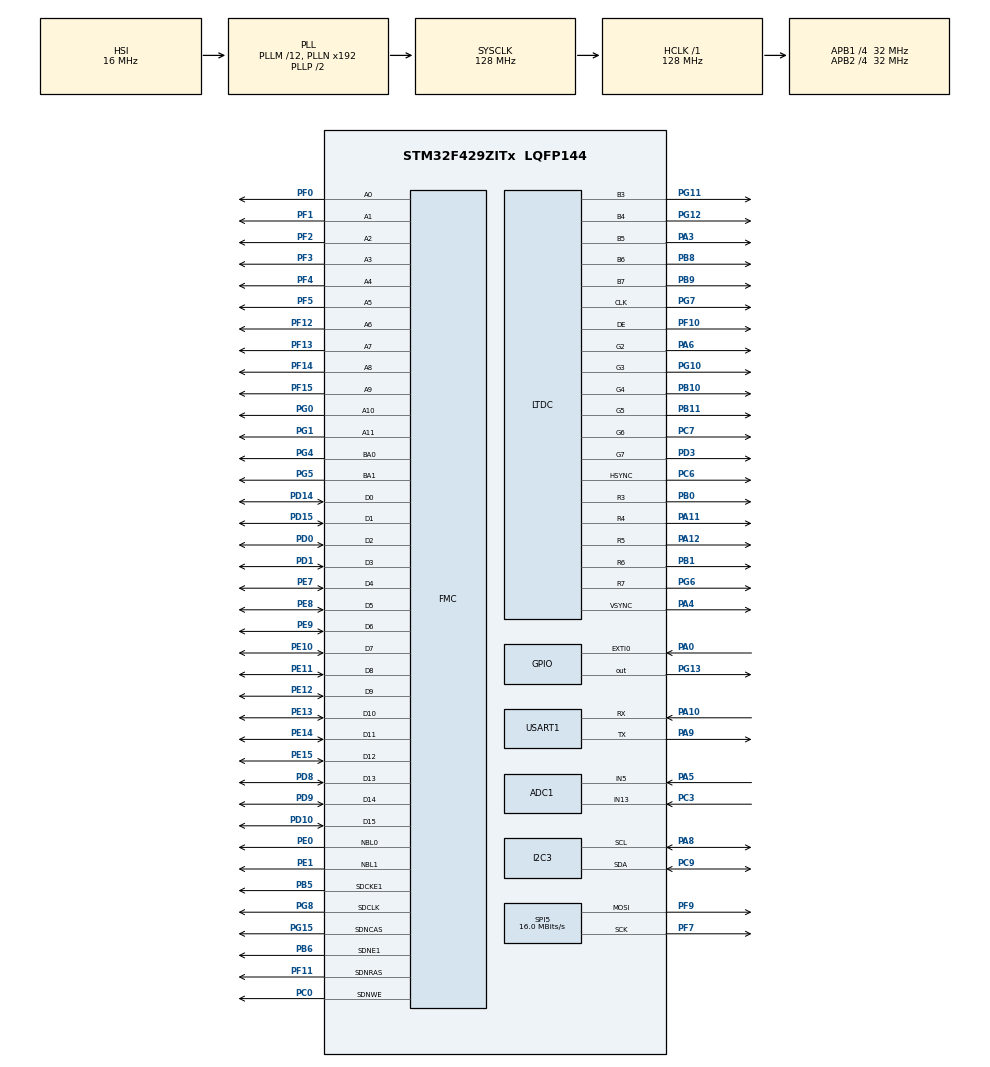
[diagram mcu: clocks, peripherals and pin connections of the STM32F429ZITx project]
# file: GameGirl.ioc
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ADC1.Channel-1\#ChannelRegularConversion=ADC_CHANNEL_5
ADC1.Channel-2\#ChannelRegularConversion=ADC_CHANNEL_13
ADC1.ContinuousConvMode=ENABLE
ADC1.DMAContinuousRequests=ENABLE
ADC1.EOCSelection=ADC_EOC_SEQ_CONV
ADC1.NbrOfConversion=2
ADC1.NbrOfConversionFlag=1
ADC1.Rank-1\#ChannelRegularConversion=1
ADC1.Rank-2\#ChannelRegularConversion=2
ADC1.SamplingTime-1\#ChannelRegularConversion=ADC_SAMPLETIME_480CYCLES
ADC1.SamplingTime-2\#ChannelRegularConversion=ADC_SAMPLETIME_480CYCLES
ADC1.ScanConvMode=ENABLE
ADC1.master=1
Dma.ADC1.0.Direction=DMA_PERIPH_TO_MEMORY
Dma.ADC1.0.FIFOMode=DMA_FIFOMODE_DISABLE
Dma.ADC1.0.Instance=DMA2_Stream0
Dma.ADC1.0.MemDataAlignment=DMA_MDATAALIGN_HALFWORD
Dma.ADC1.0.MemInc=DMA_MINC_ENABLE
Dma.ADC1.0.Mode=DMA_CIRCULAR
Dma.ADC1.0.PeriphDataAlignment=DMA_PDATAALIGN_HALFWORD
Dma.ADC1.0.PeriphInc=DMA_PINC_DISABLE
Dma.ADC1.0.Priority=DMA_PRIORITY_LOW
Dma.Request0=ADC1
FMC.CASLatency2=FMC_SDRAM_CAS_LATENCY_3
FMC.ExitSelfRefreshDelay2=7
FMC.LoadToActiveDelay2=2
FMC.RCDDelay2=2
FMC.RPDelay1=2
FMC.RPDelay2=2
FMC.ReadBurst1=FMC_SDRAM_RBURST_ENABLE
FMC.ReadBurst2=FMC_SDRAM_RBURST_ENABLE
FMC.ReadPipeDelay1=FMC_SDRAM_RPIPE_DELAY_1
FMC.ReadPipeDelay2=FMC_SDRAM_RPIPE_DELAY_1
FMC.RowCycleDelay1=7
FMC.RowCycleDelay2=7
FMC.SDClockPeriod1=FMC_SDRAM_CLOCK_PERIOD_2
FMC.SDClockPeriod2=FMC_SDRAM_CLOCK_PERIOD_2
FMC.SelfRefreshTime2=4
FMC.WriteRecoveryTime2=3
LTDC.ActiveH=320
LTDC.ActiveW=240
LTDC.Alpha_L0=255
LTDC.Blue_L0=1
LTDC.HBP=20
LTDC.HFP=10
LTDC.HSync=10
LTDC.ImageHeight_L0=320
LTDC.ImageWidth_L0=240
LTDC.Layers=0
LTDC.PixelFormat_L0=LTDC_PIXEL_FORMAT_RGB565
LTDC.Red=1
LTDC.VFP=4
LTDC.VSync=2
LTDC.WindowX1_L0=240
LTDC.WindowY1_L0=320
Mcu.Family=STM32F4
Mcu.Name=STM32F429ZITx
Mcu.Package=LQFP144
NVIC.DMA2_Stream0_IRQn=true\:0\:0\:false\:false\:true\:false\:true\:true
NVIC.EXTI0_IRQn=true\:0\:0\:false\:false\:true\:true\:true\:true
NVIC.PriorityGroup=NVIC_PRIORITYGROUP_4
PA0/WKUP.Signal=GPXTI0
PA10.Mode=Asynchronous
PA10.Signal=USART1_RX
PA11.Mode=RGB565
PA11.Signal=LTDC_R4
PA12.Mode=RGB565
PA12.Signal=LTDC_R5
PA3.Mode=RGB565
PA3.Signal=LTDC_B5
PA4.Mode=RGB565
PA4.Signal=LTDC_VSYNC
PA5.Signal=ADCx_IN5
PA6.Mode=RGB565
PA6.Signal=LTDC_G2
PA8.Mode=I2C
PA8.Signal=I2C3_SCL
PA9.Mode=Asynchronous
PA9.Signal=USART1_TX
PB0.Mode=RGB565
PB0.Signal=LTDC_R3
PB1.Mode=RGB565
PB1.Signal=LTDC_R6
PB10.Mode=RGB565
PB10.Signal=LTDC_G4
PB11.Mode=RGB565
PB11.Signal=LTDC_G5
PB5.Mode=SdramChipSelect2_2
PB5.Signal=FMC_SDCKE1
PB6.Mode=SdramChipSelect2_2
PB6.Signal=FMC_SDNE1
PB8.Mode=RGB565
PB8.Signal=LTDC_B6
PB9.Mode=RGB565
PB9.Signal=LTDC_B7
PC0.Signal=FMC_SDNWE
PC3.Signal=ADCx_IN13
PC6.Mode=RGB565
PC6.Signal=LTDC_HSYNC
PC7.Mode=RGB565
PC7.Signal=LTDC_G6
PC9.Mode=I2C
PC9.Signal=I2C3_SDA
PD0.Signal=FMC_D2_DA2
PD1.Signal=FMC_D3_DA3
PD10.Signal=FMC_D15_DA15
PD14.Signal=FMC_D0_DA0
PD15.Signal=FMC_D1_DA1
PD3.Mode=RGB565
PD3.Signal=LTDC_G7
PD8.Signal=FMC_D13_DA13
PD9.Signal=FMC_D14_DA14
PE0.Signal=FMC_NBL0
PE1.Signal=FMC_NBL1
PE10.Signal=FMC_D7_DA7
PE11.Signal=FMC_D8_DA8
PE12.Signal=FMC_D9_DA9
PE13.Signal=FMC_D10_DA10
PE14.Signal=FMC_D11_DA11
PE15.Signal=FMC_D12_DA12
PE7.Signal=FMC_D4_DA4
PE8.Signal=FMC_D5_DA5
PE9.Signal=FMC_D6_DA6
PF0.Signal=FMC_A0
PF1.Signal=FMC_A1
PF10.Mode=RGB565
PF10.Signal=LTDC_DE
PF11.Signal=FMC_SDNRAS
PF12.Signal=FMC_A6
PF13.Signal=FMC_A7
PF14.Signal=FMC_A8
PF15.Signal=FMC_A9
PF2.Signal=FMC_A2
PF3.Signal=FMC_A3
PF4.Signal=FMC_A4
PF5.Signal=FMC_A5
PF7.Mode=TX_Only_Simplex_Unidirect_Master
PF7.Signal=SPI5_SCK
PF9.Mode=TX_Only_Simplex_Unidirect_Master
PF9.Signal=SPI5_MOSI
PG0.Signal=FMC_A10
PG1.Signal=FMC_A11
PG10.Mode=RGB565
PG10.Signal=LTDC_G3
PG11.Mode=RGB565
PG11.Signal=LTDC_B3
PG12.Mode=RGB565
PG12.Signal=LTDC_B4
PG13.Signal=GPIO_Output
PG15.Signal=FMC_SDNCAS
PG4.Signal=FMC_A14_BA0
PG5.Signal=FMC_A15_BA1
PG6.Mode=RGB565
PG6.Signal=LTDC_R7
PG7.Mode=RGB565
PG7.Signal=LTDC_CLK
PG8.Signal=FMC_SDCLK
ProjectManager.HeapSize=0x200
ProjectManager.StackSize=0x400
ProjectManager.TargetToolchain=Makefile
RCC.48MHZClocksFreq_Value=64000000
RCC.AHBFreq_Value=128000000
RCC.APB1CLKDivider=RCC_HCLK_DIV4
RCC.APB1Freq_Value=32000000
RCC.APB1TimFreq_Value=64000000
RCC.APB2CLKDivider=RCC_HCLK_DIV4
RCC.APB2Freq_Value=32000000
RCC.APB2TimFreq_Value=64000000
RCC.CortexFreq_Value=128000000
RCC.HCLKFreq_Value=128000000
RCC.HSE_VALUE=25000000
RCC.HSI_VALUE=16000000
RCC.LSE_VALUE=32768
RCC.PLLM=12
RCC.PLLSAIDivR=RCC_PLLSAIDIVR_8
RCC.PLLSAIN=144
RCC.PLLSAIR=4
RCC.SYSCLKFreq_VALUE=128000000
RCC.SYSCLKSource=RCC_SYSCLKSOURCE_PLLCLK
RCC.VCOOutputFreq_Value=256000000
SH.ADCx_IN13.0=ADC1_IN13,IN13
SH.ADCx_IN5.0=ADC1_IN5,IN5
SH.FMC_A0.0=FMC_A0,12b-sda2
SH.FMC_A1.0=FMC_A1,12b-sda2
SH.FMC_A10.0=FMC_A10,12b-sda2
SH.FMC_A11.0=FMC_A11,12b-sda2
SH.FMC_A14_BA0.0=FMC_BA0,FourSdramBanks2
SH.FMC_A15_BA1.0=FMC_BA1,FourSdramBanks2
SH.FMC_A2.0=FMC_A2,12b-sda2
SH.FMC_A3.0=FMC_A3,12b-sda2
SH.FMC_A4.0=FMC_A4,12b-sda2
SH.FMC_A5.0=FMC_A5,12b-sda2
SH.FMC_A6.0=FMC_A6,12b-sda2
SH.FMC_A7.0=FMC_A7,12b-sda2
SH.FMC_A8.0=FMC_A8,12b-sda2
SH.FMC_A9.0=FMC_A9,12b-sda2
SH.FMC_D0_DA0.0=FMC_D0,sd-16b-d2
SH.FMC_D10_DA10.0=FMC_D10,sd-16b-d2
SH.FMC_D11_DA11.0=FMC_D11,sd-16b-d2
SH.FMC_D12_DA12.0=FMC_D12,sd-16b-d2
SH.FMC_D13_DA13.0=FMC_D13,sd-16b-d2
SH.FMC_D14_DA14.0=FMC_D14,sd-16b-d2
SH.FMC_D15_DA15.0=FMC_D15,sd-16b-d2
SH.FMC_D1_DA1.0=FMC_D1,sd-16b-d2
SH.FMC_D2_DA2.0=FMC_D2,sd-16b-d2
SH.FMC_D3_DA3.0=FMC_D3,sd-16b-d2
SH.FMC_D4_DA4.0=FMC_D4,sd-16b-d2
SH.FMC_D5_DA5.0=FMC_D5,sd-16b-d2
SH.FMC_D6_DA6.0=FMC_D6,sd-16b-d2
SH.FMC_D7_DA7.0=FMC_D7,sd-16b-d2
SH.FMC_D8_DA8.0=FMC_D8,sd-16b-d2
SH.FMC_D9_DA9.0=FMC_D9,sd-16b-d2
SH.FMC_NBL0.0=FMC_NBL0,Sd2ByteEnable2
SH.FMC_NBL1.0=FMC_NBL1,Sd2ByteEnable2
SH.FMC_SDCLK.0=FMC_SDCLK,12b-sda2
SH.FMC_SDNCAS.0=FMC_SDNCAS,12b-sda2
SH.FMC_SDNRAS.0=FMC_SDNRAS,12b-sda2
SH.FMC_SDNWE.0=FMC_SDNWE,12b-sda2
SPI5.CalculateBaudRate=16.0 MBits/s
SPI5.Direction=SPI_DIRECTION_2LINES
SPI5.Mode=SPI_MODE_MASTER
SPI5.VirtualType=VM_MASTER
USART1.VirtualMode=VM_ASYNC
board=custom

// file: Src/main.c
/* USER CODE BEGIN Header */
/**
  ******************************************************************************
  * @file           : main.c
  * @brief          : Main program body
  ******************************************************************************
  * @attention
  *
  * Copyright (c) 2026 STMicroelectronics.
  * All rights reserved.
  *
  * This software is licensed under terms that can be found in the LICENSE file
  * in the root directory of this software component.
  * If no LICENSE file comes with this software, it is provided AS-IS.
  *
  ******************************************************************************
  */
/* USER CODE END Header */
#include "main.h"

/* USER CODE BEGIN Includes */
#include <stdio.h>
#include <stdbool.h>
#include "display.h"
#include "menu.h"
#include "input.h"

/* USER CODE END Includes */

ADC_HandleTypeDef hadc1;
DMA_HandleTypeDef hdma_adc1;

I2C_HandleTypeDef hi2c3;

LTDC_HandleTypeDef hltdc;

SPI_HandleTypeDef hspi5;

UART_HandleTypeDef huart1;

SDRAM_HandleTypeDef hsdram2;

/* USER CODE BEGIN PV */

double tab[30][40] = {0};

volatile uint16_t joy_adc[2];   /* [0] = X (canal 5), [1] = Y (canal 13) */

volatile uint8_t button_pressed = 0;

/* USER CODE END PV */

void SystemClock_Config(void);
static void MX_GPIO_Init(void);
static void MX_DMA_Init(void);
static void MX_LTDC_Init(void);
static void MX_SPI5_Init(void);
static void MX_FMC_Init(void);
static void MX_I2C3_Init(void);
static void MX_ADC1_Init(void);
static void MX_USART1_UART_Init(void);

/* USER CODE BEGIN 0 */

#define SDRAM_TIMEOUT 0xFFFF

/* Séquence d'init JEDEC de la SDRAM IS42S16400J (FMC bank 2) */
static void SDRAM_InitSequence(SDRAM_HandleTypeDef *hsdram)
{
  FMC_SDRAM_CommandTypeDef cmd = {0};

  /* 1. Activer l'horloge SDRAM */
  cmd.CommandMode            = FMC_SDRAM_CMD_CLK_ENABLE;
  cmd.CommandTarget          = FMC_SDRAM_CMD_TARGET_BANK2;
  cmd.AutoRefreshNumber      = 1;
  cmd.ModeRegisterDefinition = 0;
  HAL_SDRAM_SendCommand(hsdram, &cmd, SDRAM_TIMEOUT);

  HAL_Delay(1);  /* >= 100 us requis */

  /* 2. Precharge All */
  cmd.CommandMode = FMC_SDRAM_CMD_PALL;
  HAL_SDRAM_SendCommand(hsdram, &cmd, SDRAM_TIMEOUT);

  /* 3. Auto-refresh x8 */
  cmd.CommandMode       = FMC_SDRAM_CMD_AUTOREFRESH_MODE;
  cmd.AutoRefreshNumber = 8;
  HAL_SDRAM_SendCommand(hsdram, &cmd, SDRAM_TIMEOUT);

  /* 4. Load Mode Register : burst 1, séquentiel, CAS 3, write burst single */
  cmd.CommandMode            = FMC_SDRAM_CMD_LOAD_MODE;
  cmd.AutoRefreshNumber      = 1;
  cmd.ModeRegisterDefinition = 0x0230;
  HAL_SDRAM_SendCommand(hsdram, &cmd, SDRAM_TIMEOUT);

  /* 5. Refresh : 64 ms / 4096 lignes = 15.62 us ; 15.62 us * 64 MHz - 20 = 980 */
  HAL_SDRAM_ProgramRefreshRate(hsdram, 980);
}

/* USER CODE END 0 */

int main(void)
{

  /* MCU Configuration--------------------------------------------------------*/

  /* Reset of all peripherals, Initializes the Flash interface and the Systick. */
  HAL_Init();

  /* Configure the system clock */
  SystemClock_Config();

  /* Initialize all configured peripherals */
  MX_GPIO_Init();
  MX_DMA_Init();
  MX_LTDC_Init();
  MX_SPI5_Init();
  MX_FMC_Init();
  MX_I2C3_Init();
  MX_ADC1_Init();
  MX_USART1_UART_Init();
  /* USER CODE BEGIN 2 */

  /* printf non bufferisé : chaque caractère part tout de suite, même sans \n */
  setvbuf(stdout, NULL, _IONBF, 0);

  SDRAM_InitSequence(&hsdram2);

  HAL_ADC_Start_DMA(&hadc1, (uint32_t *)joy_adc, 2);

  display_init();

  print_menu();

  joy_mv_t joy = get_joy();

  joy_mv_t selection = selection_joy(joy);

  /* USER CODE END 2 */

  /* Infinite loop */
  /* USER CODE BEGIN WHILE */
  while (1)
  {
    if (button_pressed)
    {
      button_pressed = 0;
      HAL_GPIO_TogglePin(GPIOG, GPIO_PIN_13);
      start_game();
      print_menu();
    }

    selection = selection_joy();

    if(new_selection())
    {
      printf("selection X : %d    selection Y = %d \r\n", selection.x, selection.y);
      menu_move((joy_mv_t){selection.x, selection.y});
      print_menu();
    }

    //printf("X = %u  %d  Y = %u  %d\r\n", value_x, selection.x, value_y, selection.y);
    HAL_Delay(100);
    /* USER CODE END WHILE */

  }
}

void SystemClock_Config(void)
{
  RCC_OscInitTypeDef RCC_OscInitStruct = {0};
  RCC_ClkInitTypeDef RCC_ClkInitStruct = {0};

  /** Configure the main internal regulator output voltage
  */
  __HAL_RCC_PWR_CLK_ENABLE();
  __HAL_PWR_VOLTAGESCALING_CONFIG(PWR_REGULATOR_VOLTAGE_SCALE2);

  /** Initializes the RCC Oscillators according to the specified parameters
  * in the RCC_OscInitTypeDef structure.
  */
  RCC_OscInitStruct.OscillatorType = RCC_OSCILLATORTYPE_HSI;
  RCC_OscInitStruct.HSIState = RCC_HSI_ON;
  RCC_OscInitStruct.HSICalibrationValue = RCC_HSICALIBRATION_DEFAULT;
  RCC_OscInitStruct.PLL.PLLState = RCC_PLL_ON;
  RCC_OscInitStruct.PLL.PLLSource = RCC_PLLSOURCE_HSI;
  RCC_OscInitStruct.PLL.PLLM = 12;
  RCC_OscInitStruct.PLL.PLLN = 192;
  RCC_OscInitStruct.PLL.PLLP = RCC_PLLP_DIV2;
  RCC_OscInitStruct.PLL.PLLQ = 4;
  if (HAL_RCC_OscConfig(&RCC_OscInitStruct) != HAL_OK)
  {
    Error_Handler();
  }

  /** Initializes the CPU, AHB and APB buses clocks
  */
  RCC_ClkInitStruct.ClockType = RCC_CLOCKTYPE_HCLK|RCC_CLOCKTYPE_SYSCLK
                              |RCC_CLOCKTYPE_PCLK1|RCC_CLOCKTYPE_PCLK2;
  RCC_ClkInitStruct.SYSCLKSource = RCC_SYSCLKSOURCE_PLLCLK;
  RCC_ClkInitStruct.AHBCLKDivider = RCC_SYSCLK_DIV1;
  RCC_ClkInitStruct.APB1CLKDivider = RCC_HCLK_DIV4;
  RCC_ClkInitStruct.APB2CLKDivider = RCC_HCLK_DIV4;

  if (HAL_RCC_ClockConfig(&RCC_ClkInitStruct, FLASH_LATENCY_4) != HAL_OK)
  {
    Error_Handler();
  }
}

static void MX_ADC1_Init(void)
{

  ADC_ChannelConfTypeDef sConfig = {0};

  /** Configure the global features of the ADC (Clock, Resolution, Data Alignment and number of conversion)
  */
  hadc1.Instance = ADC1;
  hadc1.Init.ClockPrescaler = ADC_CLOCK_SYNC_PCLK_DIV2;
  hadc1.Init.Resolution = ADC_RESOLUTION_12B;
  hadc1.Init.ScanConvMode = ENABLE;
  hadc1.Init.ContinuousConvMode = ENABLE;
  hadc1.Init.DiscontinuousConvMode = DISABLE;
  hadc1.Init.ExternalTrigConvEdge = ADC_EXTERNALTRIGCONVEDGE_NONE;
  hadc1.Init.ExternalTrigConv = ADC_SOFTWARE_START;
  hadc1.Init.DataAlign = ADC_DATAALIGN_RIGHT;
  hadc1.Init.NbrOfConversion = 2;
  hadc1.Init.DMAContinuousRequests = ENABLE;
  hadc1.Init.EOCSelection = ADC_EOC_SEQ_CONV;
  if (HAL_ADC_Init(&hadc1) != HAL_OK)
  {
    Error_Handler();
  }

  /** Configure for the selected ADC regular channel its corresponding rank in the sequencer and its sample time.
  */
  sConfig.Channel = ADC_CHANNEL_5;
  sConfig.Rank = 1;
  sConfig.SamplingTime = ADC_SAMPLETIME_480CYCLES;
  if (HAL_ADC_ConfigChannel(&hadc1, &sConfig) != HAL_OK)
  {
    Error_Handler();
  }

  /** Configure for the selected ADC regular channel its corresponding rank in the sequencer and its sample time.
  */
  sConfig.Channel = ADC_CHANNEL_13;
  sConfig.Rank = 2;
  if (HAL_ADC_ConfigChannel(&hadc1, &sConfig) != HAL_OK)
  {
    Error_Handler();
  }

}

static void MX_I2C3_Init(void)
{

  hi2c3.Instance = I2C3;
  hi2c3.Init.ClockSpeed = 100000;
  hi2c3.Init.DutyCycle = I2C_DUTYCYCLE_2;
  hi2c3.Init.OwnAddress1 = 0;
  hi2c3.Init.AddressingMode = I2C_ADDRESSINGMODE_7BIT;
  hi2c3.Init.DualAddressMode = I2C_DUALADDRESS_DISABLE;
  hi2c3.Init.OwnAddress2 = 0;
  hi2c3.Init.GeneralCallMode = I2C_GENERALCALL_DISABLE;
  hi2c3.Init.NoStretchMode = I2C_NOSTRETCH_DISABLE;
  if (HAL_I2C_Init(&hi2c3) != HAL_OK)
  {
    Error_Handler();
  }

  /** Configure Analogue filter
  */
  if (HAL_I2CEx_ConfigAnalogFilter(&hi2c3, I2C_ANALOGFILTER_ENABLE) != HAL_OK)
  {
    Error_Handler();
  }

  /** Configure Digital filter
  */
  if (HAL_I2CEx_ConfigDigitalFilter(&hi2c3, 0) != HAL_OK)
  {
    Error_Handler();
  }

}

static void MX_LTDC_Init(void)
{

  LTDC_LayerCfgTypeDef pLayerCfg = {0};

  hltdc.Instance = LTDC;
  hltdc.Init.HSPolarity = LTDC_HSPOLARITY_AL;
  hltdc.Init.VSPolarity = LTDC_VSPOLARITY_AL;
  hltdc.Init.DEPolarity = LTDC_DEPOLARITY_AL;
  hltdc.Init.PCPolarity = LTDC_PCPOLARITY_IPC;
  hltdc.Init.HorizontalSync = 9;
  hltdc.Init.VerticalSync = 1;
  hltdc.Init.AccumulatedHBP = 29;
  hltdc.Init.AccumulatedVBP = 3;
  hltdc.Init.AccumulatedActiveW = 269;
  hltdc.Init.AccumulatedActiveH = 323;
  hltdc.Init.TotalWidth = 279;
  hltdc.Init.TotalHeigh = 327;
  hltdc.Init.Backcolor.Blue = 0;
  hltdc.Init.Backcolor.Green = 0;
  hltdc.Init.Backcolor.Red = 1;
  if (HAL_LTDC_Init(&hltdc) != HAL_OK)
  {
    Error_Handler();
  }
  pLayerCfg.WindowX0 = 0;
  pLayerCfg.WindowX1 = 240;
  pLayerCfg.WindowY0 = 0;
  pLayerCfg.WindowY1 = 320;
  pLayerCfg.PixelFormat = LTDC_PIXEL_FORMAT_RGB565;
  pLayerCfg.Alpha = 255;
  pLayerCfg.Alpha0 = 0;
  pLayerCfg.BlendingFactor1 = LTDC_BLENDING_FACTOR1_CA;
  pLayerCfg.BlendingFactor2 = LTDC_BLENDING_FACTOR2_CA;
  pLayerCfg.FBStartAdress = 0;
  pLayerCfg.ImageWidth = 240;
  pLayerCfg.ImageHeight = 320;
  pLayerCfg.Backcolor.Blue = 1;
  pLayerCfg.Backcolor.Green = 0;
  pLayerCfg.Backcolor.Red = 0;
  if (HAL_LTDC_ConfigLayer(&hltdc, &pLayerCfg, 0) != HAL_OK)
  {
    Error_Handler();
  }

}

static void MX_SPI5_Init(void)
{

  /* SPI5 parameter configuration*/
  hspi5.Instance = SPI5;
  hspi5.Init.Mode = SPI_MODE_MASTER;
  hspi5.Init.Direction = SPI_DIRECTION_2LINES;
  hspi5.Init.DataSize = SPI_DATASIZE_8BIT;
  hspi5.Init.CLKPolarity = SPI_POLARITY_LOW;
  hspi5.Init.CLKPhase = SPI_PHASE_1EDGE;
  hspi5.Init.NSS = SPI_NSS_SOFT;
  hspi5.Init.BaudRatePrescaler = SPI_BAUDRATEPRESCALER_2;
  hspi5.Init.FirstBit = SPI_FIRSTBIT_MSB;
  hspi5.Init.TIMode = SPI_TIMODE_DISABLE;
  hspi5.Init.CRCCalculation = SPI_CRCCALCULATION_DISABLE;
  hspi5.Init.CRCPolynomial = 10;
  if (HAL_SPI_Init(&hspi5) != HAL_OK)
  {
    Error_Handler();
  }

}

static void MX_USART1_UART_Init(void)
{

  huart1.Instance = USART1;
  huart1.Init.BaudRate = 115200;
  huart1.Init.WordLength = UART_WORDLENGTH_8B;
  huart1.Init.StopBits = UART_STOPBITS_1;
  huart1.Init.Parity = UART_PARITY_NONE;
  huart1.Init.Mode = UART_MODE_TX_RX;
  huart1.Init.HwFlowCtl = UART_HWCONTROL_NONE;
  huart1.Init.OverSampling = UART_OVERSAMPLING_16;
  if (HAL_UART_Init(&huart1) != HAL_OK)
  {
    Error_Handler();
  }

}

static void MX_DMA_Init(void)
{

  /* DMA controller clock enable */
  __HAL_RCC_DMA2_CLK_ENABLE();

  /* DMA interrupt init */
  /* DMA2_Stream0_IRQn interrupt configuration */
  HAL_NVIC_SetPriority(DMA2_Stream0_IRQn, 0, 0);
  HAL_NVIC_EnableIRQ(DMA2_Stream0_IRQn);

}

/* FMC initialization function */
static void MX_FMC_Init(void)
{

  FMC_SDRAM_TimingTypeDef SdramTiming = {0};

  /** Perform the SDRAM2 memory initialization sequence
  */
  hsdram2.Instance = FMC_SDRAM_DEVICE;
  /* hsdram2.Init */
  hsdram2.Init.SDBank = FMC_SDRAM_BANK2;
  hsdram2.Init.ColumnBitsNumber = FMC_SDRAM_COLUMN_BITS_NUM_8;
  hsdram2.Init.RowBitsNumber = FMC_SDRAM_ROW_BITS_NUM_12;
  hsdram2.Init.MemoryDataWidth = FMC_SDRAM_MEM_BUS_WIDTH_16;
  hsdram2.Init.InternalBankNumber = FMC_SDRAM_INTERN_BANKS_NUM_4;
  hsdram2.Init.CASLatency = FMC_SDRAM_CAS_LATENCY_3;
  hsdram2.Init.WriteProtection = FMC_SDRAM_WRITE_PROTECTION_DISABLE;
  hsdram2.Init.SDClockPeriod = FMC_SDRAM_CLOCK_PERIOD_2;
  hsdram2.Init.ReadBurst = FMC_SDRAM_RBURST_ENABLE;
  hsdram2.Init.ReadPipeDelay = FMC_SDRAM_RPIPE_DELAY_1;
  /* SdramTiming */
  SdramTiming.LoadToActiveDelay = 2;
  SdramTiming.ExitSelfRefreshDelay = 7;
  SdramTiming.SelfRefreshTime = 4;
  SdramTiming.RowCycleDelay = 7;
  SdramTiming.WriteRecoveryTime = 3;
  SdramTiming.RPDelay = 2;
  SdramTiming.RCDDelay = 2;

  if (HAL_SDRAM_Init(&hsdram2, &SdramTiming) != HAL_OK)
  {
    Error_Handler( );
  }

}

static void MX_GPIO_Init(void)
{
  GPIO_InitTypeDef GPIO_InitStruct = {0};

  /* GPIO Ports Clock Enable */
  __HAL_RCC_GPIOF_CLK_ENABLE();
  __HAL_RCC_GPIOC_CLK_ENABLE();
  __HAL_RCC_GPIOA_CLK_ENABLE();
  __HAL_RCC_GPIOB_CLK_ENABLE();
  __HAL_RCC_GPIOG_CLK_ENABLE();
  __HAL_RCC_GPIOE_CLK_ENABLE();
  __HAL_RCC_GPIOD_CLK_ENABLE();

  /*Configure GPIO pin Output Level */
  HAL_GPIO_WritePin(GPIOG, GPIO_PIN_13, GPIO_PIN_RESET);

  /*Configure GPIO pin : PA0 */
  GPIO_InitStruct.Pin = GPIO_PIN_0;
  GPIO_InitStruct.Mode = GPIO_MODE_IT_RISING;
  GPIO_InitStruct.Pull = GPIO_NOPULL;
  HAL_GPIO_Init(GPIOA, &GPIO_InitStruct);

  /*Configure GPIO pin : PG13 */
  GPIO_InitStruct.Pin = GPIO_PIN_13;
  GPIO_InitStruct.Mode = GPIO_MODE_OUTPUT_PP;
  GPIO_InitStruct.Pull = GPIO_NOPULL;
  GPIO_InitStruct.Speed = GPIO_SPEED_FREQ_LOW;
  HAL_GPIO_Init(GPIOG, &GPIO_InitStruct);

  /* EXTI interrupt init*/
  HAL_NVIC_SetPriority(EXTI0_IRQn, 0, 0);
  HAL_NVIC_EnableIRQ(EXTI0_IRQn);

}

/* USER CODE BEGIN 4 */

/* Redirige printf vers l'UART1 (appelé par _write dans syscalls.c) */
int __io_putchar(int ch)
{
  uint8_t c = ch;
  HAL_UART_Transmit(&huart1, &c, 1, HAL_MAX_DELAY);
  return ch;
}

void HAL_GPIO_EXTI_Callback(uint16_t GPIO_Pin)
{
  if (GPIO_Pin == GPIO_PIN_0)
  {
    button_pressed = 1;
  }
}

/* USER CODE END 4 */

void Error_Handler(void)
{
  __disable_irq();
  while (1)
  {
  }
}
